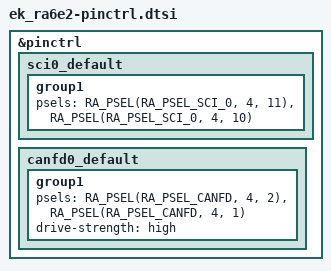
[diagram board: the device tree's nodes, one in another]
/*
 * Copyright (c) 2024 Renesas Electronics Corporation
 * SPDX-License-Identifier: Apache-2.0
 */

&pinctrl {
	sci0_default: sci0_default {
		group1 {
			/* tx rx */
			psels = <RA_PSEL(RA_PSEL_SCI_0, 4, 11)>,
			<RA_PSEL(RA_PSEL_SCI_0, 4, 10)>;
		};
	};

	canfd0_default: canfd0_default {
		group1 {
			/* CRX0 CTX0 */
			psels = <RA_PSEL(RA_PSEL_CANFD, 4, 2)>,
			<RA_PSEL(RA_PSEL_CANFD, 4, 1)>;
			drive-strength = "high";
		};
	};
};
